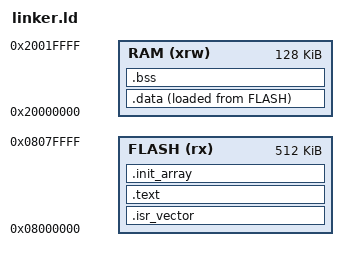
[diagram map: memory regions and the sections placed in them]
/* STM32F446RE: 512 KB flash at 0x08000000, 128 KB SRAM at 0x20000000 */

ENTRY(Reset_Handler)

MEMORY
{
    FLASH (rx)  : ORIGIN = 0x08000000, LENGTH = 512K
    RAM   (xrw) : ORIGIN = 0x20000000, LENGTH = 128K
}

/* Stack grows down from the top of RAM */
_estack = ORIGIN(RAM) + LENGTH(RAM);

SECTIONS
{
    .isr_vector :
    {
        . = ALIGN(4);
        KEEP(*(.isr_vector))
        . = ALIGN(4);
    } > FLASH

    .text :
    {
        . = ALIGN(4);
        *(.text*)
        *(.rodata*)
        . = ALIGN(4);
    } > FLASH

    .init_array :
    {
        . = ALIGN(4);
        __init_array_start = .;
        KEEP(*(SORT(.init_array.*)))
        KEEP(*(.init_array))
        __init_array_end = .;
        . = ALIGN(4);
    } > FLASH

    /* Initial values of .data are stored in flash and copied to RAM at startup */
    _sidata = LOADADDR(.data);

    .data :
    {
        . = ALIGN(4);
        _sdata = .;
        *(.data*)
        . = ALIGN(4);
        _edata = .;
    } > RAM AT > FLASH

    .bss :
    {
        . = ALIGN(4);
        _sbss = .;
        *(.bss*)
        *(COMMON)
        . = ALIGN(4);
        _ebss = .;
    } > RAM

    /DISCARD/ :
    {
        *(.ARM.exidx*)
        *(.ARM.extab*)
        *(.eh_frame*)
    }
}
